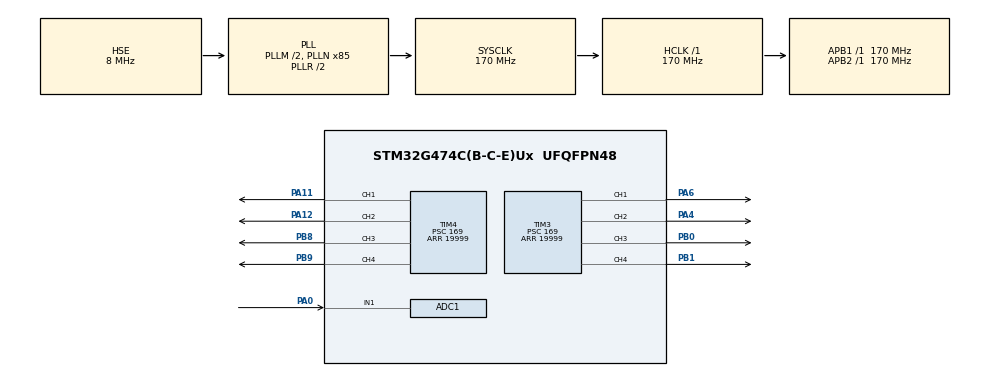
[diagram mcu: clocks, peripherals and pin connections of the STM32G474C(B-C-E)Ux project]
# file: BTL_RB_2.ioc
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ADC1.Channel-0\#ChannelRegularConversion=ADC_CHANNEL_1
ADC1.ContinuousConvMode=ENABLE
ADC1.GainCompensation=0
ADC1.NbrOfConversion=1
ADC1.NbrOfConversionFlag=1
ADC1.OffsetNumber-0\#ChannelRegularConversion=ADC_OFFSET_NONE
ADC1.OversamplingMode=DISABLE
ADC1.Rank-0\#ChannelRegularConversion=1
ADC1.SamplingTime-0\#ChannelRegularConversion=ADC_SAMPLETIME_2CYCLES_5
ADC1.master=1
Mcu.Family=STM32G4
Mcu.Name=STM32G474C(B-C-E)Ux
Mcu.Package=UFQFPN48
NVIC.PriorityGroup=NVIC_PRIORITYGROUP_4
PA0.Mode=IN1-Single-Ended
PA0.Signal=ADC1_IN1
PA11.Signal=S_TIM4_CH1
PA12.Signal=S_TIM4_CH2
PA13.Mode=Serial_Wire
PA13.Signal=SYS_JTMS-SWDIO
PA14.Mode=Serial_Wire
PA14.Signal=SYS_JTCK-SWCLK
PA4.Signal=S_TIM3_CH2
PA6.Signal=S_TIM3_CH1
PB0.Signal=S_TIM3_CH3
PB1.Signal=S_TIM3_CH4
PB8-BOOT0.Signal=S_TIM4_CH3
PB9.Signal=S_TIM4_CH4
PF0-OSC_IN.Mode=HSE-External-Oscillator
PF0-OSC_IN.Signal=RCC_OSC_IN
PF1-OSC_OUT.Mode=HSE-External-Oscillator
PF1-OSC_OUT.Signal=RCC_OSC_OUT
ProjectManager.HeapSize=0x200
ProjectManager.StackSize=0x400
ProjectManager.TargetToolchain=STM32CubeIDE
RCC.ADC12Freq_Value=170000000
RCC.ADC345Freq_Value=170000000
RCC.AHBFreq_Value=170000000
RCC.APB1Freq_Value=170000000
RCC.APB1TimFreq_Value=170000000
RCC.APB2Freq_Value=170000000
RCC.APB2TimFreq_Value=170000000
RCC.CortexFreq_Value=170000000
RCC.EXTERNAL_CLOCK_VALUE=12288000
RCC.HCLKFreq_Value=170000000
RCC.HSE_VALUE=8000000
RCC.HSI48_VALUE=48000000
RCC.HSI_VALUE=16000000
RCC.LSE_VALUE=32768
RCC.PLLM=RCC_PLLM_DIV2
RCC.PLLN=85
RCC.PLLSourceVirtual=RCC_PLLSOURCE_HSE
RCC.SYSCLKFreq_VALUE=170000000
RCC.SYSCLKSource=RCC_SYSCLKSOURCE_PLLCLK
RCC.USBFreq_Value=170000000
RCC.VCOOutputFreq_Value=340000000
SH.S_TIM3_CH1.0=TIM3_CH1,PWM Generation1 CH1
SH.S_TIM3_CH2.0=TIM3_CH2,PWM Generation2 CH2
SH.S_TIM3_CH3.0=TIM3_CH3,PWM Generation3 CH3
SH.S_TIM3_CH4.0=TIM3_CH4,PWM Generation4 CH4
SH.S_TIM4_CH1.0=TIM4_CH1,PWM Generation1 CH1
SH.S_TIM4_CH2.0=TIM4_CH2,PWM Generation2 CH2
SH.S_TIM4_CH3.0=TIM4_CH3,PWM Generation3 CH3
SH.S_TIM4_CH4.0=TIM4_CH4,PWM Generation4 CH4
TIM3.AutoReloadPreload=TIM_AUTORELOAD_PRELOAD_ENABLE
TIM3.Channel-PWM\ Generation1\ CH1=TIM_CHANNEL_1
TIM3.Channel-PWM\ Generation2\ CH2=TIM_CHANNEL_2
TIM3.Channel-PWM\ Generation3\ CH3=TIM_CHANNEL_3
TIM3.Channel-PWM\ Generation4\ CH4=TIM_CHANNEL_4
TIM3.OCFastMode_PWM-PWM\ Generation1\ CH1=TIM_OCFAST_ENABLE
TIM3.OCFastMode_PWM-PWM\ Generation2\ CH2=TIM_OCFAST_ENABLE
TIM3.OCFastMode_PWM-PWM\ Generation3\ CH3=TIM_OCFAST_ENABLE
TIM3.OCFastMode_PWM-PWM\ Generation4\ CH4=TIM_OCFAST_ENABLE
TIM3.PeriodNoDither=19999
TIM3.Prescaler=169
TIM3.PulseNoDither_1=1500
TIM3.PulseNoDither_3=1500
TIM3.PulseNoDither_4=1500
TIM4.AutoReloadPreload=TIM_AUTORELOAD_PRELOAD_ENABLE
TIM4.Channel-PWM\ Generation1\ CH1=TIM_CHANNEL_1
TIM4.Channel-PWM\ Generation2\ CH2=TIM_CHANNEL_2
TIM4.Channel-PWM\ Generation3\ CH3=TIM_CHANNEL_3
TIM4.Channel-PWM\ Generation4\ CH4=TIM_CHANNEL_4
TIM4.OCFastMode_PWM-PWM\ Generation1\ CH1=TIM_OCFAST_ENABLE
TIM4.OCFastMode_PWM-PWM\ Generation2\ CH2=TIM_OCFAST_ENABLE
TIM4.PeriodNoDither=19999
TIM4.Prescaler=169
TIM4.PulseNoDither_1=1500
TIM4.PulseNoDither_2=1500
VP_SYS_VS_DBSignals.Mode=DisableDeadBatterySignals
VP_TIM3_VS_ClockSourceINT.Mode=Internal
VP_TIM4_VS_ClockSourceINT.Mode=Internal
board=custom

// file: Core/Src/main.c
/* USER CODE BEGIN Header */
/**
 ******************************************************************************
 * @file           : main.c
 * @brief          : Main program body
 ******************************************************************************
 * @attention
 *
 * Copyright (c) 2026 STMicroelectronics.
 * All rights reserved.
 *
 * This software is licensed under terms that can be found in the LICENSE file
 * in the root directory of this software component.
 * If no LICENSE file comes with this software, it is provided AS-IS.
 *
 ******************************************************************************
 */
/* USER CODE END Header */
#include "main.h"
#include "adc.h"
#include "gpio.h"
#include "tim.h"

/* USER CODE BEGIN Includes */
#include "robot_joint.h"
#include "servo_feedback.h"
/* USER CODE END Includes */

/* USER CODE BEGIN PV */
RbJoint_t robot;           /* Global robot arm instance */
ServoFeedback_t fb_j4;     /* J4 feedback — watch in Live Expressions */
float j4_calibrated_angle; /* Angle relative to calibrated zero */
/* USER CODE END PV */

void SystemClock_Config(void);

int main(void) {

  /* MCU Configuration--------------------------------------------------------*/

  /* Reset of all peripherals, Initializes the Flash interface and the Systick.
   */
  HAL_Init();

  /* Configure the system clock */
  SystemClock_Config();

  /* Initialize all configured peripherals */
  MX_GPIO_Init();
  MX_TIM3_Init();
  MX_TIM4_Init();
  MX_ADC1_Init();
  /* USER CODE BEGIN 2 */

  /* Initialise robot joints (starts PWM, moves to home = 0°) */
  RbJoint_Init(&robot);

  /* Initialise ADC for J4 feedback (PA0 → ADC1_IN1) */
  ServoFB_Init();

  /* USER CODE END 2 */

  /* Infinite loop */
  /* USER CODE BEGIN WHILE */
  while (1) {
    /* Debug: thay đổi robot.joint[i].current_angle trong Live Expressions */
    for (int i = 0; i < RB_NUM_JOINTS; i++)
      RbJoint_SetAngle(&robot, (RbJointIndex_e)i, robot.joint[i].current_angle);

    /* Đọc feedback J4 */
    ServoFB_Read(&fb_j4);
    j4_calibrated_angle = ServoFB_GetCalibratedAngle(&fb_j4);

    HAL_Delay(20); /* 50Hz update */
    /* USER CODE END WHILE */

  }
}

void SystemClock_Config(void) {
  RCC_OscInitTypeDef RCC_OscInitStruct = {0};
  RCC_ClkInitTypeDef RCC_ClkInitStruct = {0};

  /** Configure the main internal regulator output voltage
   */
  HAL_PWREx_ControlVoltageScaling(PWR_REGULATOR_VOLTAGE_SCALE1_BOOST);

  /** Initializes the RCC Oscillators according to the specified parameters
   * in the RCC_OscInitTypeDef structure.
   */
  RCC_OscInitStruct.OscillatorType = RCC_OSCILLATORTYPE_HSE;
  RCC_OscInitStruct.HSEState = RCC_HSE_ON;
  RCC_OscInitStruct.PLL.PLLState = RCC_PLL_ON;
  RCC_OscInitStruct.PLL.PLLSource = RCC_PLLSOURCE_HSE;
  RCC_OscInitStruct.PLL.PLLM = RCC_PLLM_DIV2;
  RCC_OscInitStruct.PLL.PLLN = 85;
  RCC_OscInitStruct.PLL.PLLP = RCC_PLLP_DIV2;
  RCC_OscInitStruct.PLL.PLLQ = RCC_PLLQ_DIV2;
  RCC_OscInitStruct.PLL.PLLR = RCC_PLLR_DIV2;
  if (HAL_RCC_OscConfig(&RCC_OscInitStruct) != HAL_OK) {
    Error_Handler();
  }

  /** Initializes the CPU, AHB and APB buses clocks
   */
  RCC_ClkInitStruct.ClockType = RCC_CLOCKTYPE_HCLK | RCC_CLOCKTYPE_SYSCLK |
                                RCC_CLOCKTYPE_PCLK1 | RCC_CLOCKTYPE_PCLK2;
  RCC_ClkInitStruct.SYSCLKSource = RCC_SYSCLKSOURCE_PLLCLK;
  RCC_ClkInitStruct.AHBCLKDivider = RCC_SYSCLK_DIV1;
  RCC_ClkInitStruct.APB1CLKDivider = RCC_HCLK_DIV1;
  RCC_ClkInitStruct.APB2CLKDivider = RCC_HCLK_DIV1;

  if (HAL_RCC_ClockConfig(&RCC_ClkInitStruct, FLASH_LATENCY_4) != HAL_OK) {
    Error_Handler();
  }
}

void Error_Handler(void) {
  __disable_irq();
  while (1) {
  }
}
#ifdef USE_FULL_ASSERT
/**
 * @brief  Reports the name of the source file and the source line number
 *         where the assert_param error has occurred.
 * @param  file: pointer to the source file name
 * @param  line: assert_param error line source number
 * @retval None
 */
void assert_failed(uint8_t *file, uint32_t line) {
  /* USER CODE BEGIN 6 */
  /* User can add his own implementation to report the file name and line
     number, ex: printf("Wrong parameters value: file %s on line %d\r\n", file,
     line) */
  /* USER CODE END 6 */
}
#endif /* USE_FULL_ASSERT */
